# PIC32MX154F128D register map
Vendor: Microchip
Registers are 32-bit, read-write, reset 0x0 unless marked. A register's access mark holds for its fields unless they carry their own. Addresses are absolute, and some are shared; only a register's first bit layout is shown; [hi:lo] are bit positions; {n}, {i} and the like mark numbered series.

## DMAC3
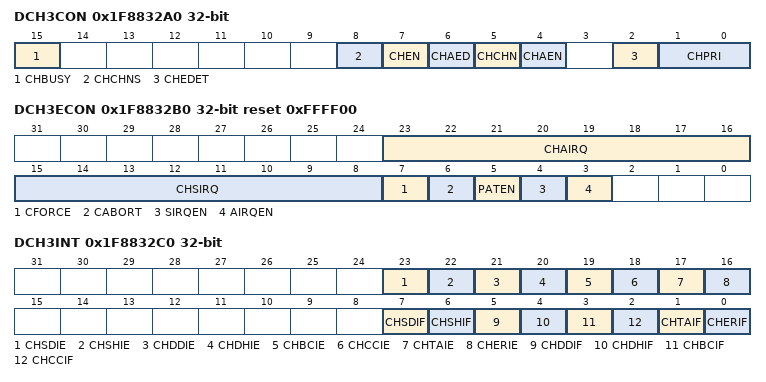
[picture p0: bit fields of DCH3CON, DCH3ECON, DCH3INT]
0x1F8832A0 DCH3CON reset not defined — (power-on value ----------------x------00000-000)
  [15] CHBUSY, [8] CHCHNS, [7] CHEN, [6] CHAED, [5] CHCHN, [4] CHAEN, [2] CHEDET ro, [1:0] CHPRI
0x1F8832B0 DCH3ECON reset 0xFFFF00
  [23:16] CHAIRQ
  [15:8] CHSIRQ
  [7] CFORCE — (can only be set)
  [6] CABORT — (can only be set)
  [5] PATEN
  [4] SIRQEN
  [3] AIRQEN
0x1F8832C0 DCH3INT
  [23] CHSDIE, [22] CHSHIE, [21] CHDDIE, [20] CHDHIE, [19] CHBCIE, [18] CHCCIE, [17] CHTAIE, [16] CHERIE, [7] CHSDIF, [6] CHSHIF, [5] CHDDIF, [4] CHDHIF, [3] CHBCIF, [2] CHCCIF, [1] CHTAIF, [0] CHERIF
0x1F8832D0 DCH3SSA reset not defined — (power-on value xxxxxxxxxxxxxxxxxxxxxxxxxxxxxxxx)
0x1F8832E0 DCH3DSA reset not defined — (power-on value xxxxxxxxxxxxxxxxxxxxxxxxxxxxxxxx)
0x1F8832F0 DCH3SSIZ reset not defined — (power-on value ----------------xxxxxxxxxxxxxxxx)
  [15:0] CHSSIZ
0x1F883300 DCH3DSIZ reset not defined — (power-on value ----------------xxxxxxxxxxxxxxxx)
  [15:0] CHDSIZ
0x1F883310 DCH3SPTR reset not defined — (power-on value ----------------xxxxxxxxxxxxxxxx)
  [15:0] CHSPTR
0x1F883320 DCH3DPTR ro
  [15:0] CHDPTR
0x1F883330 DCH3CSIZ reset not defined — (power-on value ----------------xxxxxxxxxxxxxxxx)
  [15:0] CHCSIZ
0x1F883340 DCH3CPTR reset not defined — (power-on value ----------------xxxxxxxxxxxxxxxx)
  [15:0] CHCPTR
0x1F883350 DCH3DAT reset not defined — (power-on value ------------------------xxxxxxxx)
  [7:0] DCHPDAT

## PCACHE
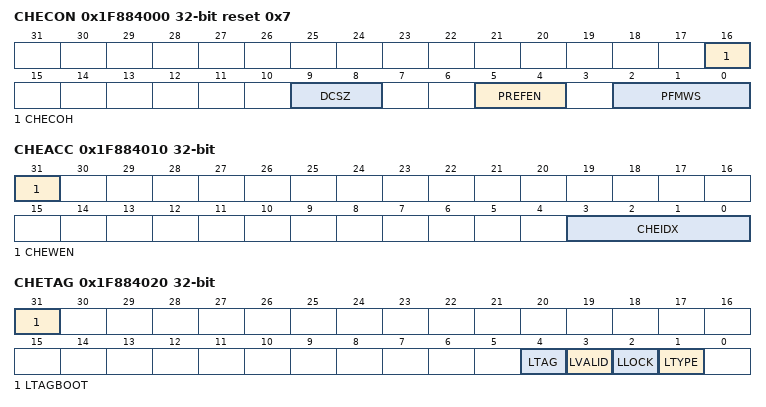
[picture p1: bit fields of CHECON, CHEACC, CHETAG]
0x1F884000 CHECON reset 0x7
  [16] CHECOH, [9:8] DCSZ, [5:4] PREFEN, [2:0] PFMWS
0x1F884010 CHEACC
  [31] CHEWEN, [3:0] CHEIDX
0x1F884020 CHETAG reset not defined — (power-on value 0xxxxxxxxxxxxxxxxxxxxxxxxxxx0010)
  [31] LTAGBOOT, [4] LTAG, [3] LVALID, [2] LLOCK, [1] LTYPE
0x1F884030 CHEMSK
  [15:5] LMASK
{0x1F884040+0x10*i} CHEW{i} reset not defined (i=0..3) — (power-on value xxxxxxxxxxxxxxxxxxxxxxxxxxxxxxxx)
0x1F884080 CHELRU
  [24:0] CHELRU
0x1F884090 CHEHIT reset not defined — (power-on value xxxxxxxxxxxxxxxxxxxxxxxxxxxxxxxx)
  [31:0] CHEHIT — (can only be cleared)
0x1F8840A0 CHEMIS reset not defined — (power-on value xxxxxxxxxxxxxxxxxxxxxxxxxxxxxxxx)
  [31:0] CHEMIS — (can only be cleared)
0x1F8840C0 CHEPFABT reset not defined — (power-on value xxxxxxxxxxxxxxxxxxxxxxxxxxxxxxxx)
  [31:0] CHEPFABT — (can only be cleared)

## TRAA_Ports
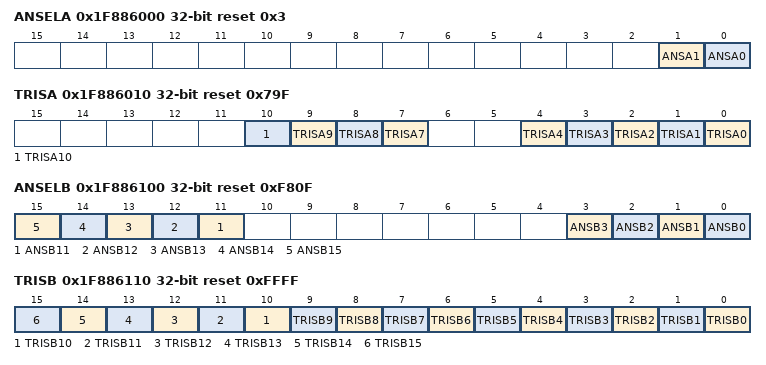
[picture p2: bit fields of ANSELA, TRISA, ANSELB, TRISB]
0x1F886000 ANSELA reset 0x3
  [1] ANSA1, [0] ANSA0
0x1F886010 TRISA reset 0x79F
  [n] TRISA{n} (n=7..10), [n] TRISA{n} (n=0..4)
0x1F886100 ANSELB reset 0xF80F
  [n] ANSB{n} (n=11..15), [n] ANSB{n} (n=0..3)
0x1F886110 TRISB reset 0xFFFF
  [n] TRISB{n} (n=0..15)
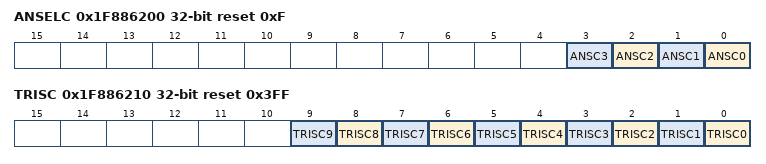
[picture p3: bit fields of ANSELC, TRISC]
0x1F886200 ANSELC reset 0xF
  [n] ANSC{n} (n=0..3)
0x1F886210 TRISC reset 0x3FF
  [n] TRISC{n} (n=0..9)

## PORTA
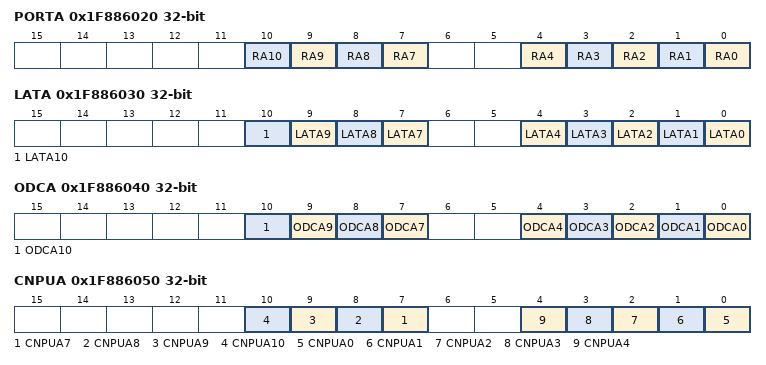
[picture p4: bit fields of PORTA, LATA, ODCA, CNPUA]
0x1F886020 PORTA reset not defined — (power-on value ---------------------xxxx--xxxxx)
  [n] RA{n} (n=7..10), [n] RA{n} (n=0..4)
0x1F886030 LATA reset not defined — (power-on value ---------------------xxxx--xxxxx)
  [n] LATA{n} (n=7..10), [n] LATA{n} (n=0..4)
0x1F886040 ODCA
  [n] ODCA{n} (n=7..10), [n] ODCA{n} (n=0..4)
0x1F886050 CNPUA reset not defined — (power-on value ---------------------xxxx--xxxxx)
  [n] CNPUA{n} (n=7..10), [n] CNPUA{n} (n=0..4)
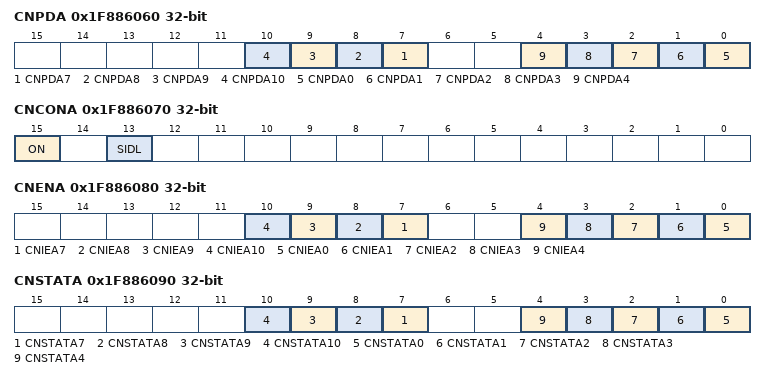
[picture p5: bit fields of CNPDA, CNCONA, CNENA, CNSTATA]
0x1F886060 CNPDA reset not defined — (power-on value ---------------------xxxx--xxxxx)
  [n] CNPDA{n} (n=7..10), [n] CNPDA{n} (n=0..4)
0x1F886070 CNCONA
  [15] ON, [13] SIDL
0x1F886080 CNENA reset not defined — (power-on value 0000000000-----------xxxx--xxxxx)
  [n] CNIEA{n} (n=7..10), [n] CNIEA{n} (n=0..4)
0x1F886090 CNSTATA reset not defined — (power-on value ---------------------xxxx--xxxxx)
  [n] CNSTATA{n} (n=7..10), [n] CNSTATA{n} (n=0..4)

## PORTB
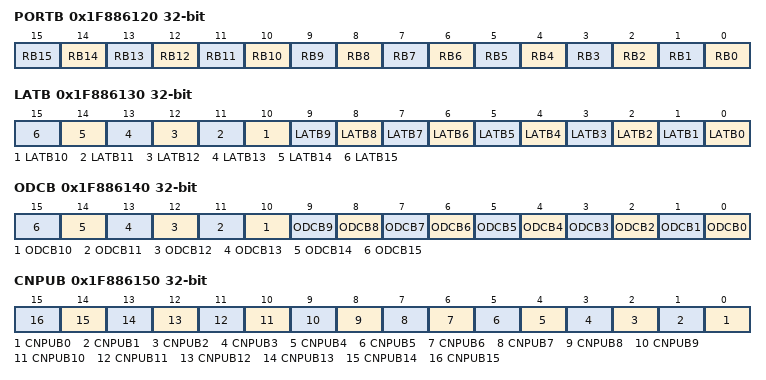
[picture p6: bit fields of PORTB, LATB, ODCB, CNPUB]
0x1F886120 PORTB reset not defined — (power-on value ----------------xxxxxxxxxxxxxxxx)
  [n] RB{n} (n=0..15)
0x1F886130 LATB reset not defined — (power-on value ----------------xxxxxxxxxxxxxxxx)
  [n] LATB{n} (n=0..15)
0x1F886140 ODCB
  [n] ODCB{n} (n=0..15)
0x1F886150 CNPUB reset not defined — (power-on value ----------------xxxxxxxxxxxxxxxx)
  [n] CNPUB{n} (n=0..15)
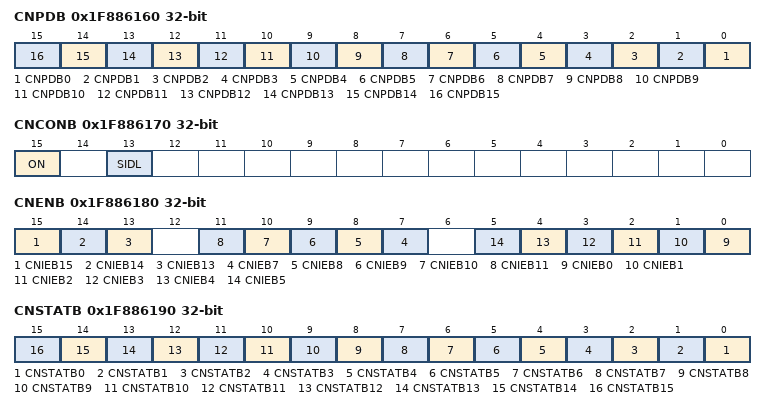
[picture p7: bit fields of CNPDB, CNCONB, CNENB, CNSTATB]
0x1F886160 CNPDB reset not defined — (power-on value ----------------xxxxxxxxxxxxxxxx)
  [n] CNPDB{n} (n=0..15)
0x1F886170 CNCONB
  [15] ON, [13] SIDL
0x1F886180 CNENB reset not defined — (power-on value 0000000000------xxx-xxxxx-xxxxxx)
  [15] CNIEB15, [14] CNIEB14, [13] CNIEB13, [n] CNIEB{n} (n=7..11), [n] CNIEB{n} (n=0..5)
0x1F886190 CNSTATB reset not defined — (power-on value ----------------xxxxxxxxxxxxxxxx)
  [n] CNSTATB{n} (n=0..15)

## PORTC
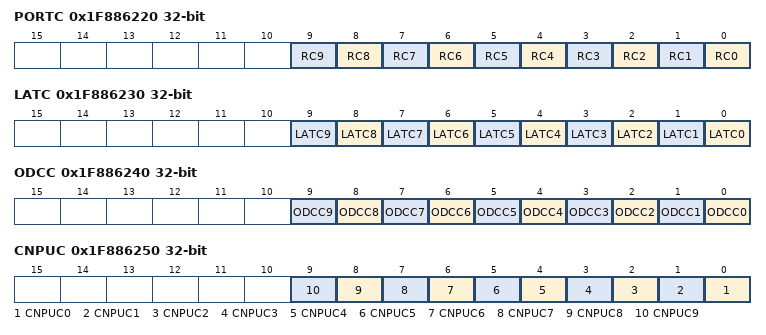
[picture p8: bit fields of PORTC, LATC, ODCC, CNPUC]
0x1F886220 PORTC reset not defined — (power-on value ----------------------xxxxxxxxxx)
  [n] RC{n} (n=0..9)
0x1F886230 LATC reset not defined — (power-on value ----------------------xxxxxxxxxx)
  [n] LATC{n} (n=0..9)
0x1F886240 ODCC
  [n] ODCC{n} (n=0..9)
0x1F886250 CNPUC reset not defined — (power-on value ----------------------xxxxxxxxxx)
  [n] CNPUC{n} (n=0..9)
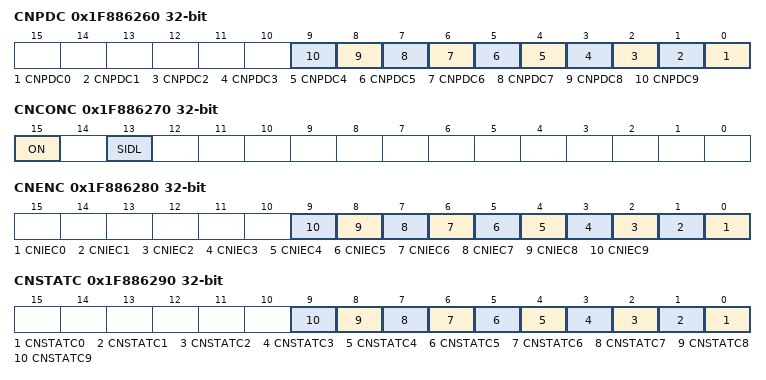
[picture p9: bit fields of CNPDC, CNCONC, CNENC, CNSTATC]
0x1F886260 CNPDC reset not defined — (power-on value ----------------------xxxxxxxxxx)
  [n] CNPDC{n} (n=0..9)
0x1F886270 CNCONC
  [15] ON, [13] SIDL
0x1F886280 CNENC reset not defined — (power-on value 0000000000------------xxxxxxxxxx)
  [n] CNIEC{n} (n=0..9)
0x1F886290 CNSTATC reset not defined — (power-on value ----------------------xxxxxxxxxx)
  [n] CNSTATC{n} (n=0..9)
